AUTOSAR XML (schema 00049)
package /ISOFT/PlatformComponents/sm/swc
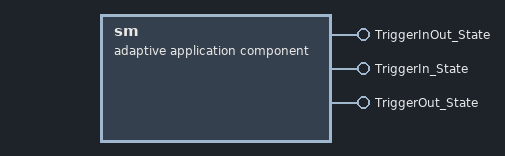
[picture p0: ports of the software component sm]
  adaptive application sw component type sm
    provide port TriggerInOut_State: provided-interface=TriggerInOut_State
    provide port TriggerIn_State: provided-interface=TriggerIn_State
    provide port TriggerOut_State: provided-interface=TriggerOut_State
